# PIC32MX254F128D device description
Architecture: MIPS; Family: PIC32MX; Series: PIC32MX
Registers are 32-bit, read-write, no defined reset value unless marked. A register's access mark holds for its fields unless they carry their own. Offsets are from the block's base; [hi:lo] are bit positions; {n}, {i} and the like mark numbered series; 'fields as' and 'values as' point back to an identical list.

## RPIN
Instances: RPIN 0x1f80fa04 in periph1
0x00 INT1R
  [3:0] INT1R
0x04 INT2R
  [3:0] INT2R
0x08 INT3R
  [3:0] INT3R
0x0C INT4R
  [3:0] INT4R
{0xC+4i} T{i}CKR (i=2..5)
  [3:0] T{i}CKR
{0x20+4i} IC{i}R (i=1..5)
  [3:0] IC{i}R
0x44 OCFAR
  [3:0] OCFAR
0x48 OCFBR
  [3:0] OCFBR
0x4C U1RXR
  [3:0] U1RXR
0x50 U1CTSR
  [3:0] U1CTSR
0x54 U2RXR
  [3:0] U2RXR
0x58 U2CTSR
  [3:0] U2CTSR
0x80 SDI1R
  [3:0] SDI1R
0x84 SS1R
  [3:0] SS1R
0x8C SDI2R
  [3:0] SDI2R
0x90 SS2R
  [3:0] SS2R
0xB4 REFCLKIR
  [3:0] REFCLKIR

## RPOUT
Instances: RPOUT 0x1f80fb00 in periph1
{0x0+4i} RPA{i}R (i=0..4)
  [3:0] RPA{i}R
0x20 RPA8R
  [3:0] RPA8R
0x24 RPA9R
  [3:0] RPA9R
{0x2C+4i} RPB{i}R (i=0..11)
  [3:0] RPB{i}R
{0x2C+4i} RPB{i}R (i=13..15)
  [3:0] RPB{i}R
{0x6C+4i} RPC{i}R (i=0..9)
  [3:0] RPC{i}R

## TMR1
Instances: TMR1 0x1f800600 in periph0
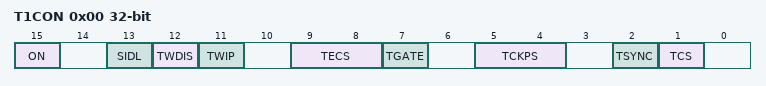
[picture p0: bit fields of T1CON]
0x00 T1CON — TYPE A TIMER CONTROL REGISTER
  [15] ON — Timer On bit
    1=Timer is enabled; 0=Timer is disabled
  [13] SIDL — Stop in Idle Mode bit
    1=Discontinue operation when device enters Idle mode; 0=Continue operation even in Idle mode
  [12] TWDIS — Asynchronous Timer Write Disable bit
    1=Writes to TMR1 are ignored until pending write operation completes; 0=Back-to-back writes are enabled (Legacy Asynchronous Timer functionality)
  [11] TWIP — Asynchronous Timer Write in Progress bit
    1=(In Asynchronous Timer mode) Asynchronous write to TMR1 register in progress / (In Synchronous Timer mode)bit is read as 0; 0=In Asynchronous Timer mode Asynchronous write to TMR1 register complete / (In Synchronous Timer mode)bit is read as 0
  [9:8] TECS — Timer1 External Clock Selection bits
    2=External clock comes from the LPRC; 1=External clock comes from the T1CK pin; 0=External clock comes from the SOSC
  [7] TGATE — Timer Gated Time Accumulation Enable bit
    1=(When TCS is 0) Gated time accumulation is enabled / (When TCS is 1) bit is ignored; 0=(When TCS is 0) Gated time accumulation is disabled / (When TCS is 1) bit is ignored
  [5:4] TCKPS — Timer Input Clock Prescale Select bits
    3=1:256 prescale value; 2=1:64 prescale value; 1=1:8 prescale value; 0=1:1 prescale value
  [2] TSYNC — Timer External Clock Input Synchronization Selection bit
    1=(When TCS is 1) External clock input is synchronized / (When TCS is 0) This bit is ignored; 0=(When TCS is 1) External clock input is not synchronized / (When TCS is 0) This bit is ignored
  [1] TCS — Timer Clock Source Select bit
    1=External clock is defined by the TECS bits; 0=Internal peripheral clock
0x10 TMR1
0x20 PR1

## TMR
Instances: TMR 0x1f800800 in periph0
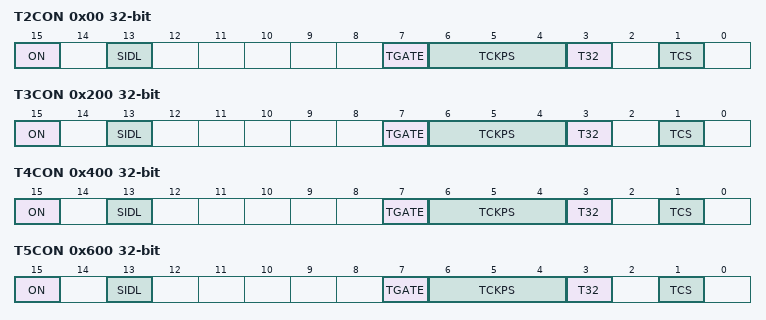
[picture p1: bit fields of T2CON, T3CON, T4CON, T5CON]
0x00 T2CON — Type B Timer Control Register
  [15] ON — Timer On bit
    1=Module is enabled; 0=Module is disabled
  [13] SIDL — Stop in Idle Mode bit
    1=Discontinue operation when device enters Idle mode; 0=Continue module operation when the device enters Idle mode
  [7] TGATE — Timer Gated Time Accumulation Enable bit
    1=(When TCS is 0): Gated time accumulation is enabled / (When TCS is 1): bit is ignored and read as 0; 0=(When TCS is 0): Gated time accumulation is disabled / (When TCS is 1): bit is ignored and read as 0
  [6:4] TCKPS — Timer Input Clock Prescale Select bits
    7=1:256 prescale value; 6=1:64 prescale value; 5=1:32 prescale value; 4=1:16 prescale value; 3=1:8 prescale value; 2=1:4 prescale value; 1=1:2 prescale value; 0=1:1 prescale value
  [3] T32 — 32-Bit Timer Mode Select bit
    1=Odd numbered and even numbered timers form a 32-bit timer; 0=Odd numbered and even numbered timers form a separate 16-bit timer
  [1] TCS — Timer Clock Source Select bit
    1=External clock from TxCK pin; 0=Internal peripheral clock
0x10 TMR2
0x20 PR2
0x200 T3CON — Type B Timer Control Register
  fields as T2CON
0x210 TMR3
0x220 PR3
0x400 T4CON — Type B Timer Control Register
  fields as T2CON
0x410 TMR4
0x420 PR4
0x600 T5CON — Type B Timer Control Register
  fields as T2CON
0x610 TMR5
0x620 PR5

## WDT
Instances: WDT 0x1f80f600 in periph1
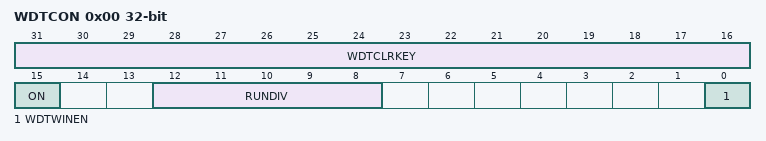
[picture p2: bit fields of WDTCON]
0x00 WDTCON — Watchdog Timer Control Register
  [31:16] WDTCLRKEY
  [15] ON — Watchdog Timer Enable bit
    1=The WDT module is enabled; 0=The WDT module is disabled
  [12:8] RUNDIV
  [0] WDTWINEN — Watchdog Timer Window Enable bit
    1=Enable windowed Watchdog Timer; 0=Disable windowed Watchdog Timer
